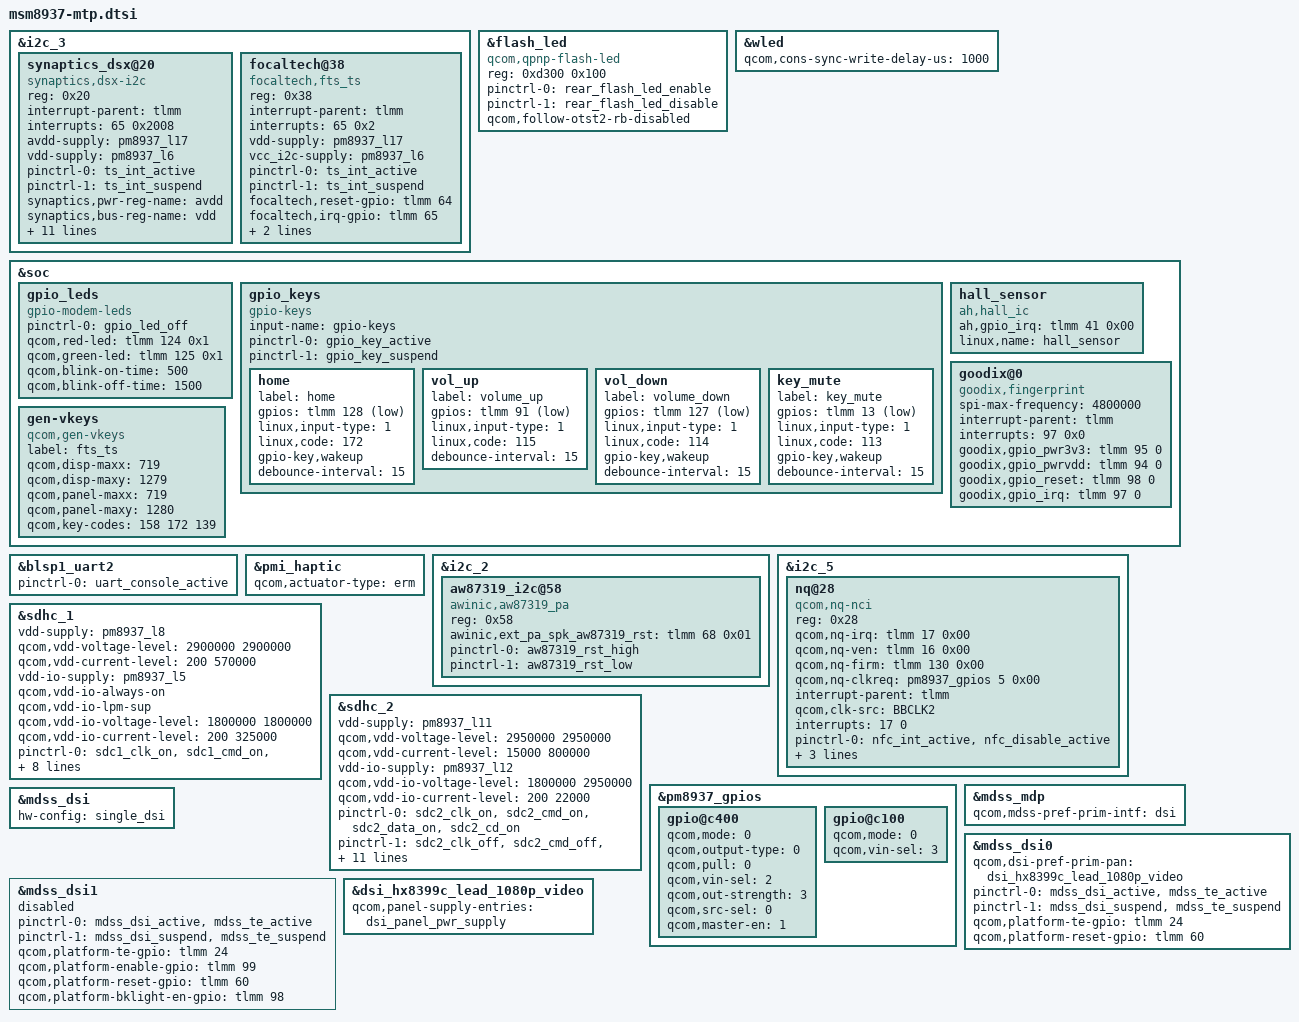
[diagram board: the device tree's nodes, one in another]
/*
 * Copyright (c) 2015-2016, The Linux Foundation. All rights reserved.
 *
 * This program is free software; you can redistribute it and/or modify
 * it under the terms of the GNU General Public License version 2 and
 * only version 2 as published by the Free Software Foundation.
 *
 * This program is distributed in the hope that it will be useful,
 * but WITHOUT ANY WARRANTY; without even the implied warranty of
 * MERCHANTABILITY or FITNESS FOR A PARTICULAR PURPOSE.  See the
 * GNU General Public License for more details.
 */

#include "msm8937-pinctrl.dtsi"
#include "msm8937-camera-sensor-mtp.dtsi"

/* add by wkh begin*/
&i2c_3 { /* BLSP1 QUP3 */
    synaptics_dsx@20 {
			compatible = "synaptics,dsx-i2c";
			reg = <0x20>;
		interrupt-parent = <&tlmm>;
			interrupts = <65 0x2008>;
		avdd-supply = <&pm8937_l17>;
		vdd-supply = <&pm8937_l6>;
		pinctrl-names = "pmx_ts_active", "pmx_ts_suspend";
		pinctrl-0 = <&ts_int_active>;
		pinctrl-1 = <&ts_int_suspend>;
		synaptics,pwr-reg-name = "avdd";
		synaptics,bus-reg-name = "vdd";
		synaptics,ub-i2c-addr = <0x2c>;
		synaptics,irq-gpio = <&tlmm 65 0x2008>; /* IRQF_ONESHOT | IRQF_TRIGGER_LOW */
		synaptics,reset-gpio = <&tlmm 64 0>;
		//synaptics,power-gpio = <&tlmm 139 0>; 
			synaptics,irq-on-state = <0>;
			synaptics,power-delay-ms = <30>;
			synaptics,reset-delay-ms = <50>;
		synaptics,power-on-state = <1>;
			synaptics,reset-on-state = <0>;
			synaptics,reset-active-ms = <20>;
			synaptics,resume-in-workqueue;
			/* uncomment and update line below as appropriate if there are 0D buttons */
			synaptics,cap-button-codes = <158 172 139>;
			/* uncomment and update lines below as appropriate if there are virtual buttons */
			/* synaptics,vir-button-codes = <102 100 900 100 60 158 300 900 100 60>; */
			/* synaptics,max-y-for-2d = <800>; */
	};
		focaltech@38{
			compatible = "focaltech,fts_ts";
			reg = <0x38>;
			interrupt-parent = <&tlmm>;
			interrupts = <65 0x2>;
			vdd-supply = <&pm8937_l17>;
			vcc_i2c-supply = <&pm8937_l6>;
			pinctrl-names = "pmx_ts_active", "pmx_ts_suspend";
			pinctrl-0 = <&ts_int_active>;
			pinctrl-1 = <&ts_int_suspend>;
			focaltech,reset-gpio = <&tlmm 64 0x0>;
			focaltech,irq-gpio = <&tlmm 65 0x2008>;
			focaltech,display-coords = <0 0 720 1280>;				
			focaltech,max-touch-number = <5>;				
			/*focaltech,resume-in-workqueue;*/
		};

};
/*  end by wkh */

&flash_led {
	compatible = "qcom,qpnp-flash-led";
	reg = <0xd300 0x100>;
	pinctrl-names = "flash_led_enable","flash_led_disable";
	pinctrl-0 = <&rear_flash_led_enable>;
	pinctrl-1 = <&rear_flash_led_disable>;
	qcom,follow-otst2-rb-disabled;
};

&wled {
	qcom,cons-sync-write-delay-us = <1000>;
};

&soc {
/* added by zte_sw_chenyingfang for color_led,start */
	gpio_leds {
		compatible = "gpio-modem-leds";
		status = "okay";
		pinctrl-names = "default";
		pinctrl-0 = <&gpio_led_off>;
		qcom,red-led = <&tlmm 124 0x1>; 
		qcom,green-led = <&tlmm 125 0x1>; 
		/*qcom,trickle_red-led = <&tlmm 3 0x1>;*/
		qcom,blink-on-time = <500>;
		qcom,blink-off-time = <1500>;
	};  
	
/* added by zte_sw_chenyingfang for color_led,end */
	gpio_keys {
		compatible = "gpio-keys";
		input-name = "gpio-keys";
		pinctrl-names = "tlmm_gpio_key_active","tlmm_gpio_key_suspend";
		pinctrl-0 = <&gpio_key_active>;
		pinctrl-1 = <&gpio_key_suspend>;

		// ZTE_MODIFY start by dingli10091962
        home {
			label = "home";
			gpios = <&tlmm 128 0x1>;
			linux,input-type = <1>;
			linux,code = <172>;
			gpio-key,wakeup;    //add by xueqiang 1114
			debounce-interval = <15>;
		};

		//camera_snapshot {
		//	label = "camera_snapshot";
		//	gpios = <&tlmm 127 0x1>;
		//	linux,input-type = <1>;
		//	linux,code = <0x2fe>;
		//	debounce-interval = <15>;
		//};
        // ZTE_MODIFY end by dingli10091962

		vol_up {
			label = "volume_up";
			gpios = <&tlmm 91 0x1>;
			linux,input-type = <1>;
			linux,code = <115>;
			debounce-interval = <15>;
		};

		// ZTE_MODIFY start by dingli10091962
        vol_down {
			label = "volume_down";
			gpios = <&tlmm 127 0x1>;
			linux,input-type = <1>;
			linux,code = <114>;
			gpio-key,wakeup;
			debounce-interval = <15>;
		};
       key_mute {
                     label = "key_mute";
			gpios = <&tlmm 13 0x1>;
			linux,input-type = <1>;
			linux,code = <113>;
			gpio-key,wakeup;
			debounce-interval = <15>;

		};

		
        // ZTE_MODIFY end by dingli10091962        
	};

	//hbtp {
	//	compatible = "qcom,hbtp-input";
	//	vcc_dig-supply = <&pm8937_l5>;
	//	qcom,dig-load = <15000>;
	//	qcom,dig-vtg-min = <1800000>;
	//	qcom,dig-vtg-max = <1800000>;
	//};

	hall_sensor {
		compatible = "ah,hall_ic";		
		ah,gpio_irq = <&tlmm 41 0x00>;
		linux,name = "hall_sensor";	
	};	
/*added by chenhui for goodix fingerprint*/
    goodix@0 {
        compatible = "goodix,fingerprint";
        spi-max-frequency = <4800000>;
        interrupt-parent = <&tlmm>;
        interrupts = <97 0x0>;
        goodix,gpio_pwr3v3 = <&tlmm 95 0>;
        goodix,gpio_pwrvdd = <&tlmm 94 0>;		
        goodix,gpio_reset = <&tlmm 98 0>;
        goodix,gpio_irq = <&tlmm 97 0>;
    }; 
/*added by chenhui for goodix fingerprint*/	

    gen-vkeys {
		compatible = "qcom,gen-vkeys";
		label = "fts_ts";
		qcom,disp-maxx = <719>;
		qcom,disp-maxy = <1279>;
		qcom,panel-maxx = <719>;
		qcom,panel-maxy = <1280>;
		qcom,key-codes = <158 172 139>;
	};
};

&blsp1_uart2 {
	status = "ok";
	pinctrl-names = "default";
	pinctrl-0 = <&uart_console_active>;
};

&pmi_haptic{
	qcom,actuator-type = "erm";
};
//lll054850 add for aw87319 20161128
&i2c_2 {
		aw87319_i2c@58{
	        compatible = "awinic,aw87319_pa";
	        reg = <0x58>;
	        awinic,ext_pa_spk_aw87319_rst = <&tlmm 68 0x01>;
	        pinctrl-names = "aw87319_pa_active", "aw87319_pa_off";
	        pinctrl-0 = <&aw87319_rst_high>;
	        pinctrl-1 = <&aw87319_rst_low>;	
        };
};
//lll054850 add for aw87319 20161128
&i2c_5 { /* BLSP2 QUP1 */
	nq@28 {
		compatible = "qcom,nq-nci";
		reg = <0x28>;
		qcom,nq-irq = <&tlmm 17 0x00>;
		qcom,nq-ven = <&tlmm 16 0x00>;
		qcom,nq-firm = <&tlmm 130 0x00>;
		qcom,nq-clkreq = <&pm8937_gpios 5 0x00>;
		interrupt-parent = <&tlmm>;
		qcom,clk-src = "BBCLK2";
		interrupts = <17 0>;
		interrupt-names = "nfc_irq";
		pinctrl-names = "nfc_active", "nfc_suspend";
		pinctrl-0 = <&nfc_int_active &nfc_disable_active>;
		pinctrl-1 = <&nfc_int_suspend &nfc_disable_suspend>;
		clocks = <&clock_gcc clk_bb_clk2_pin>;
		clock-names = "ref_clk";
	};
};

&sdhc_1 {
	/* device core power supply */
	vdd-supply = <&pm8937_l8>;
	qcom,vdd-voltage-level = <2900000 2900000>;
	qcom,vdd-current-level = <200 570000>;

	/* device communication power supply */
	vdd-io-supply = <&pm8937_l5>;
	qcom,vdd-io-always-on;
	qcom,vdd-io-lpm-sup;
	qcom,vdd-io-voltage-level = <1800000 1800000>;
	qcom,vdd-io-current-level = <200 325000>;

	pinctrl-names = "active", "sleep";
	pinctrl-0 = <&sdc1_clk_on &sdc1_cmd_on &sdc1_data_on &sdc1_rclk_on>;
	pinctrl-1 = <&sdc1_clk_off &sdc1_cmd_off &sdc1_data_off &sdc1_rclk_off>;

	qcom,clk-rates = <400000 20000000 25000000 50000000 100000000 192000000
								384000000>;
	qcom,nonremovable;
	qcom,bus-speed-mode = "HS400_1p8v", "HS200_1p8v", "DDR_1p8v";

	status = "ok";
};

&sdhc_2 {
	/* device core power supply */
	vdd-supply = <&pm8937_l11>;
	qcom,vdd-voltage-level = <2950000 2950000>;
	qcom,vdd-current-level = <15000 800000>;

	/* device communication power supply */
	vdd-io-supply = <&pm8937_l12>;
	qcom,vdd-io-voltage-level = <1800000 2950000>;
	qcom,vdd-io-current-level = <200 22000>;

	pinctrl-names = "active", "sleep";
	pinctrl-0 = <&sdc2_clk_on &sdc2_cmd_on &sdc2_data_on &sdc2_cd_on>;
	pinctrl-1 = <&sdc2_clk_off &sdc2_cmd_off &sdc2_data_off>;

	#address-cells = <0>;
	interrupt-parent = <&sdhc_2>;
	interrupts = <0 1 2>;
	#interrupt-cells = <1>;
	interrupt-map-mask = <0xffffffff>;
	interrupt-map = <0 &intc 0 125 0
		1 &intc 0 221 0
		2 &tlmm 67 0>;
	interrupt-names = "hc_irq", "pwr_irq", "status_irq";
	cd-gpios = <&tlmm 67 0x0>;

	qcom,clk-rates = <400000 20000000 25000000 50000000 100000000
								200000000>;
	qcom,bus-speed-mode = "SDR12", "SDR25", "SDR50", "DDR50", "SDR104";

	status = "ok";
};

&pm8937_gpios {
	gpio@c400 {
		qcom,mode = <0>;
		qcom,output-type = <0>;
		qcom,pull = <0>;
		qcom,vin-sel = <2>;
		qcom,out-strength = <3>;
		qcom,src-sel = <0>;
		qcom,master-en = <1>;
		status = "okay";
	};
};

#include "msm8937-mdss-panels.dtsi"

&mdss_mdp {
	qcom,mdss-pref-prim-intf = "dsi";
};

&mdss_dsi {
	hw-config = "single_dsi";
};
//modify by yujianhua start
&mdss_dsi0 {
	qcom,dsi-pref-prim-pan = <&dsi_hx8399c_lead_1080p_video>;
	pinctrl-names = "mdss_default", "mdss_sleep";
	pinctrl-0 = <&mdss_dsi_active &mdss_te_active>;
	pinctrl-1 = <&mdss_dsi_suspend &mdss_te_suspend>;

	qcom,platform-te-gpio = <&tlmm 24 0>;
	//qcom,platform-enable-gpio = <&tlmm 99 0>;
	qcom,platform-reset-gpio = <&tlmm 60 0>;
	//qcom,platform-bklight-en-gpio = <&tlmm 98 0>;
};
//modify by yujianhua end

&mdss_dsi1 {
	status = "disabled";
	//qcom,dsi-pref-prim-pan = <&dsi_truly_1080_vid>;
	pinctrl-names = "mdss_default", "mdss_sleep";
	pinctrl-0 = <&mdss_dsi_active &mdss_te_active>;
	pinctrl-1 = <&mdss_dsi_suspend &mdss_te_suspend>;

	qcom,platform-te-gpio = <&tlmm 24 0>;
	qcom,platform-enable-gpio = <&tlmm 99 0>;
	qcom,platform-reset-gpio = <&tlmm 60 0>;
	qcom,platform-bklight-en-gpio = <&tlmm 98 0>;
};

//add by zhanglian start
&dsi_hx8399c_lead_1080p_video {
	qcom,panel-supply-entries = <&dsi_panel_pwr_supply>;
};
//add by zhanglian end


/* PM8937 GPIO configuration */
&pm8937_gpios {
	gpio@c100 {
		qcom,mode = <0>;
		qcom,vin-sel = <3>;
		status = "okay";
	};
};
